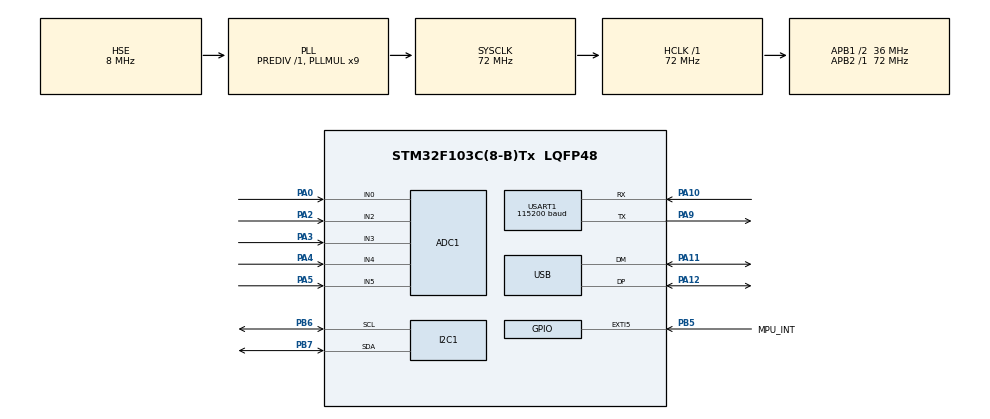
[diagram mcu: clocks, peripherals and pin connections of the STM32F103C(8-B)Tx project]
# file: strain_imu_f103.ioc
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ADC1.Channel-0\#ChannelRegularConversion=ADC_CHANNEL_2
ADC1.Channel-1\#ChannelRegularConversion=ADC_CHANNEL_0
ADC1.Channel-2\#ChannelRegularConversion=ADC_CHANNEL_3
ADC1.Channel-3\#ChannelRegularConversion=ADC_CHANNEL_4
ADC1.Channel-4\#ChannelRegularConversion=ADC_CHANNEL_5
ADC1.ContinuousConvMode=DISABLE
ADC1.NbrOfConversion=5
ADC1.NbrOfConversionFlag=1
ADC1.Rank-0\#ChannelRegularConversion=1
ADC1.Rank-1\#ChannelRegularConversion=2
ADC1.Rank-2\#ChannelRegularConversion=3
ADC1.Rank-3\#ChannelRegularConversion=4
ADC1.Rank-4\#ChannelRegularConversion=5
ADC1.SamplingTime-0\#ChannelRegularConversion=ADC_SAMPLETIME_239CYCLES_5
ADC1.SamplingTime-1\#ChannelRegularConversion=ADC_SAMPLETIME_239CYCLES_5
ADC1.SamplingTime-2\#ChannelRegularConversion=ADC_SAMPLETIME_239CYCLES_5
ADC1.SamplingTime-3\#ChannelRegularConversion=ADC_SAMPLETIME_239CYCLES_5
ADC1.SamplingTime-4\#ChannelRegularConversion=ADC_SAMPLETIME_239CYCLES_5
ADC1.ScanConvMode=ADC_SCAN_ENABLE
ADC1.master=1
Dma.Request0=USART1_TX
Dma.USART1_TX.0.Direction=DMA_MEMORY_TO_PERIPH
Dma.USART1_TX.0.Instance=DMA1_Channel4
Dma.USART1_TX.0.MemDataAlignment=DMA_MDATAALIGN_BYTE
Dma.USART1_TX.0.MemInc=DMA_MINC_ENABLE
Dma.USART1_TX.0.Mode=DMA_NORMAL
Dma.USART1_TX.0.PeriphDataAlignment=DMA_PDATAALIGN_BYTE
Dma.USART1_TX.0.PeriphInc=DMA_PINC_DISABLE
Dma.USART1_TX.0.Priority=DMA_PRIORITY_MEDIUM
Mcu.Family=STM32F1
Mcu.Name=STM32F103C(8-B)Tx
Mcu.Package=LQFP48
NVIC.DMA1_Channel4_IRQn=true\:2\:0\:false\:false\:true\:true\:false\:true
NVIC.PriorityGroup=NVIC_PRIORITYGROUP_4
NVIC.USART1_IRQn=true\:3\:0\:false\:false\:true\:true\:true\:true
NVIC.USB_LP_CAN1_RX0_IRQn=true\:4\:0\:false\:false\:true\:true\:false\:true
PA0-WKUP.Signal=ADCx_IN0
PA10.Mode=Asynchronous
PA10.Signal=USART1_RX
PA11.Mode=Device
PA11.Signal=USB_DM
PA12.Mode=Device
PA12.Signal=USB_DP
PA13.Mode=Serial_Wire
PA13.Signal=SYS_JTMS-SWDIO
PA14.Mode=Serial_Wire
PA14.Signal=SYS_JTCK-SWCLK
PA2.Signal=ADCx_IN2
PA3.Signal=ADCx_IN3
PA4.Signal=ADCx_IN4
PA5.Signal=ADCx_IN5
PA9.Mode=Asynchronous
PA9.Signal=USART1_TX
PB5.GPIO_Label=MPU_INT
PB5.GPIO_ModeDefaultEXTI=GPIO_MODE_IT_RISING
PB5.Signal=GPXTI5
PB6.Mode=I2C
PB6.Signal=I2C1_SCL
PB7.Mode=I2C
PB7.Signal=I2C1_SDA
PD0-OSC_IN.Mode=HSE-External-Oscillator
PD0-OSC_IN.Signal=RCC_OSC_IN
PD1-OSC_OUT.Mode=HSE-External-Oscillator
PD1-OSC_OUT.Signal=RCC_OSC_OUT
ProjectManager.HeapSize=0x200
ProjectManager.StackSize=0x800
ProjectManager.TargetToolchain=STM32CubeIDE
RCC.ADCPresc=RCC_ADCPCLK2_DIV6
RCC.AHBFreq_Value=72000000
RCC.APB1CLKDivider=RCC_HCLK_DIV2
RCC.APB1Freq_Value=36000000
RCC.APB1TimFreq_Value=72000000
RCC.APB2Freq_Value=72000000
RCC.APB2TimFreq_Value=72000000
RCC.HCLKFreq_Value=72000000
RCC.PLLMUL=RCC_PLL_MUL9
RCC.PLLSourceVirtual=RCC_PLLSOURCE_HSE
RCC.SYSCLKFreq_VALUE=72000000
RCC.SYSCLKSource=RCC_SYSCLKSOURCE_PLLCLK
RCC.USBFreq_Value=48000000
RCC.USBPrescaler=RCC_USBCLKSOURCE_PLL_DIV1_5
SH.ADCx_IN0.0=ADC1_IN0,IN0
SH.ADCx_IN2.0=ADC1_IN2,IN2
SH.ADCx_IN3.0=ADC1_IN3,IN3
SH.ADCx_IN4.0=ADC1_IN4,IN4
SH.ADCx_IN5.0=ADC1_IN5,IN5
USART1.BaudRate=115200
USART1.VirtualMode=VM_ASYNC
USB_DEVICE.CLASS_NAME_FS=CDC
USB_DEVICE.VirtualMode=Cdc
USB_DEVICE.VirtualModeFS=Cdc_FS
VP_USB_DEVICE_VS_USB_DEVICE_CDC_FS.Mode=CDC_FS
board=custom

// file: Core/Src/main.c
/* USER CODE BEGIN Header */
/**
  ******************************************************************************
  * @file           : main.c
  * @brief          : Main program body
  ******************************************************************************
  * @attention
  *
  * Copyright (c) 2026 STMicroelectronics.
  * All rights reserved.
  *
  * This software is licensed under terms that can be found in the LICENSE file
  * in the root directory of this software component.
  * If no LICENSE file comes with this software, it is provided AS-IS.
  *
  ******************************************************************************
  */
/* USER CODE END Header */
#include "main.h"
#include "usb_device.h"

/* USER CODE BEGIN Includes */
#include "app.h"

/* USER CODE END Includes */

ADC_HandleTypeDef hadc1;

I2C_HandleTypeDef hi2c1;

UART_HandleTypeDef huart1;
DMA_HandleTypeDef hdma_usart1_tx;

void SystemClock_Config(void);
static void MX_GPIO_Init(void);
static void MX_DMA_Init(void);
static void MX_ADC1_Init(void);
static void MX_I2C1_Init(void);
static void MX_USART1_UART_Init(void);

int main(void)
{

  /* MCU Configuration--------------------------------------------------------*/

  /* Reset of all peripherals, Initializes the Flash interface and the Systick. */
  HAL_Init();

  /* Configure the system clock */
  SystemClock_Config();

  /* Initialize all configured peripherals */
  MX_GPIO_Init();
  MX_DMA_Init();
  MX_ADC1_Init();
  MX_I2C1_Init();
  MX_USART1_UART_Init();
  MX_USB_DEVICE_Init();
  /* USER CODE BEGIN 2 */
  app_init(&hadc1, &hi2c1, &huart1);

  /* USER CODE END 2 */

  /* Infinite loop */
  while (1)
  {

    /* USER CODE BEGIN 3 */
    app_process();
  }
  /* USER CODE END 3 */
}

void SystemClock_Config(void)
{
  RCC_OscInitTypeDef RCC_OscInitStruct = {0};
  RCC_ClkInitTypeDef RCC_ClkInitStruct = {0};
  RCC_PeriphCLKInitTypeDef PeriphClkInit = {0};

  /** Initializes the RCC Oscillators according to the specified parameters
  * in the RCC_OscInitTypeDef structure.
  */
  RCC_OscInitStruct.OscillatorType = RCC_OSCILLATORTYPE_HSE;
  RCC_OscInitStruct.HSEState = RCC_HSE_ON;
  RCC_OscInitStruct.HSEPredivValue = RCC_HSE_PREDIV_DIV1;
  RCC_OscInitStruct.HSIState = RCC_HSI_ON;
  RCC_OscInitStruct.PLL.PLLState = RCC_PLL_ON;
  RCC_OscInitStruct.PLL.PLLSource = RCC_PLLSOURCE_HSE;
  RCC_OscInitStruct.PLL.PLLMUL = RCC_PLL_MUL9;
  if (HAL_RCC_OscConfig(&RCC_OscInitStruct) != HAL_OK)
  {
    Error_Handler();
  }

  /** Initializes the CPU, AHB and APB buses clocks
  */
  RCC_ClkInitStruct.ClockType = RCC_CLOCKTYPE_HCLK|RCC_CLOCKTYPE_SYSCLK
                              |RCC_CLOCKTYPE_PCLK1|RCC_CLOCKTYPE_PCLK2;
  RCC_ClkInitStruct.SYSCLKSource = RCC_SYSCLKSOURCE_PLLCLK;
  RCC_ClkInitStruct.AHBCLKDivider = RCC_SYSCLK_DIV1;
  RCC_ClkInitStruct.APB1CLKDivider = RCC_HCLK_DIV2;
  RCC_ClkInitStruct.APB2CLKDivider = RCC_HCLK_DIV1;

  if (HAL_RCC_ClockConfig(&RCC_ClkInitStruct, FLASH_LATENCY_2) != HAL_OK)
  {
    Error_Handler();
  }
  PeriphClkInit.PeriphClockSelection = RCC_PERIPHCLK_ADC|RCC_PERIPHCLK_USB;
  PeriphClkInit.AdcClockSelection = RCC_ADCPCLK2_DIV6;
  PeriphClkInit.UsbClockSelection = RCC_USBCLKSOURCE_PLL_DIV1_5;
  if (HAL_RCCEx_PeriphCLKConfig(&PeriphClkInit) != HAL_OK)
  {
    Error_Handler();
  }
}

static void MX_ADC1_Init(void)
{

  ADC_ChannelConfTypeDef sConfig = {0};

  /** Common config
  */
  hadc1.Instance = ADC1;
  hadc1.Init.ScanConvMode = ADC_SCAN_ENABLE;
  hadc1.Init.ContinuousConvMode = DISABLE;
  hadc1.Init.DiscontinuousConvMode = DISABLE;
  hadc1.Init.ExternalTrigConv = ADC_SOFTWARE_START;
  hadc1.Init.DataAlign = ADC_DATAALIGN_RIGHT;
  hadc1.Init.NbrOfConversion = 5;
  if (HAL_ADC_Init(&hadc1) != HAL_OK)
  {
    Error_Handler();
  }

  /** Configure Regular Channel
  */
  sConfig.Channel = ADC_CHANNEL_2;
  sConfig.Rank = ADC_REGULAR_RANK_1;
  sConfig.SamplingTime = ADC_SAMPLETIME_239CYCLES_5;
  if (HAL_ADC_ConfigChannel(&hadc1, &sConfig) != HAL_OK)
  {
    Error_Handler();
  }

  /** Configure Regular Channel
  */
  sConfig.Channel = ADC_CHANNEL_0;
  sConfig.Rank = ADC_REGULAR_RANK_2;
  if (HAL_ADC_ConfigChannel(&hadc1, &sConfig) != HAL_OK)
  {
    Error_Handler();
  }

  /** Configure Regular Channel
  */
  sConfig.Channel = ADC_CHANNEL_3;
  sConfig.Rank = ADC_REGULAR_RANK_3;
  if (HAL_ADC_ConfigChannel(&hadc1, &sConfig) != HAL_OK)
  {
    Error_Handler();
  }

  /** Configure Regular Channel
  */
  sConfig.Channel = ADC_CHANNEL_4;
  sConfig.Rank = ADC_REGULAR_RANK_4;
  if (HAL_ADC_ConfigChannel(&hadc1, &sConfig) != HAL_OK)
  {
    Error_Handler();
  }

  /** Configure Regular Channel
  */
  sConfig.Channel = ADC_CHANNEL_5;
  sConfig.Rank = ADC_REGULAR_RANK_5;
  if (HAL_ADC_ConfigChannel(&hadc1, &sConfig) != HAL_OK)
  {
    Error_Handler();
  }

}

static void MX_I2C1_Init(void)
{

  hi2c1.Instance = I2C1;
  hi2c1.Init.ClockSpeed = 100000;
  hi2c1.Init.DutyCycle = I2C_DUTYCYCLE_2;
  hi2c1.Init.OwnAddress1 = 0;
  hi2c1.Init.AddressingMode = I2C_ADDRESSINGMODE_7BIT;
  hi2c1.Init.DualAddressMode = I2C_DUALADDRESS_DISABLE;
  hi2c1.Init.OwnAddress2 = 0;
  hi2c1.Init.GeneralCallMode = I2C_GENERALCALL_DISABLE;
  hi2c1.Init.NoStretchMode = I2C_NOSTRETCH_DISABLE;
  if (HAL_I2C_Init(&hi2c1) != HAL_OK)
  {
    Error_Handler();
  }

}

static void MX_USART1_UART_Init(void)
{

  huart1.Instance = USART1;
  huart1.Init.BaudRate = 115200;
  huart1.Init.WordLength = UART_WORDLENGTH_8B;
  huart1.Init.StopBits = UART_STOPBITS_1;
  huart1.Init.Parity = UART_PARITY_NONE;
  huart1.Init.Mode = UART_MODE_TX_RX;
  huart1.Init.HwFlowCtl = UART_HWCONTROL_NONE;
  huart1.Init.OverSampling = UART_OVERSAMPLING_16;
  if (HAL_UART_Init(&huart1) != HAL_OK)
  {
    Error_Handler();
  }

}

static void MX_DMA_Init(void)
{

  /* DMA controller clock enable */
  __HAL_RCC_DMA1_CLK_ENABLE();

  /* DMA interrupt init */
  /* DMA1_Channel1_IRQn interrupt configuration */
  NVIC_SetPriority(DMA1_Channel1_IRQn, NVIC_EncodePriority(NVIC_GetPriorityGrouping(),2, 0));
  NVIC_EnableIRQ(DMA1_Channel1_IRQn);
  /* DMA1_Channel4_IRQn interrupt configuration */
  HAL_NVIC_SetPriority(DMA1_Channel4_IRQn, 2, 0);
  HAL_NVIC_EnableIRQ(DMA1_Channel4_IRQn);

}

static void MX_GPIO_Init(void)
{
  GPIO_InitTypeDef GPIO_InitStruct = {0};

  /* GPIO Ports Clock Enable */
  __HAL_RCC_GPIOD_CLK_ENABLE();
  __HAL_RCC_GPIOA_CLK_ENABLE();
  __HAL_RCC_GPIOB_CLK_ENABLE();

  /*Configure GPIO pin : MPU_INT_Pin */
  GPIO_InitStruct.Pin = MPU_INT_Pin;
  GPIO_InitStruct.Mode = GPIO_MODE_IT_RISING;
  GPIO_InitStruct.Pull = GPIO_NOPULL;
  HAL_GPIO_Init(MPU_INT_GPIO_Port, &GPIO_InitStruct);

}

void Error_Handler(void)
{
  __disable_irq();
  while (1)
  {
  }
}
